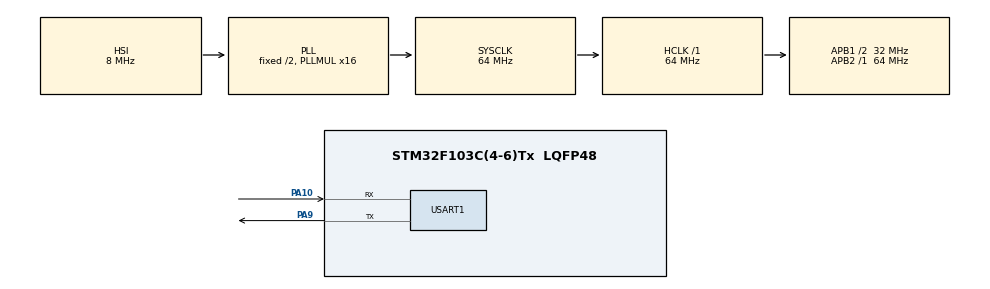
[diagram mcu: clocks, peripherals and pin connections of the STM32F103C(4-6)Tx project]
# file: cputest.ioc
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FREERTOS.Tasks01=defaultTask,0,128,StartDefaultTask,Default,NULL,Dynamic,NULL,NULL;myTask02,-3,128,StartTask02,Default,NULL,Dynamic,NULL,NULL;myTask03,-3,128,StartTask03,Default,NULL,Dynamic,NULL,NULL;monitorTask,-3,128,monitorTaskFun,Default,NULL,Dynamic,NULL,NULL
FREERTOS.configGENERATE_RUN_TIME_STATS=1
FREERTOS.configTOTAL_HEAP_SIZE=5120
FREERTOS.configUSE_STATS_FORMATTING_FUNCTIONS=1
FREERTOS.configUSE_TRACE_FACILITY=1
Mcu.Family=STM32F1
Mcu.Name=STM32F103C(4-6)Tx
Mcu.Package=LQFP48
NVIC.PriorityGroup=NVIC_PRIORITYGROUP_4
NVIC.TIM1_UP_IRQn=true\:15\:0\:false\:false\:true\:false\:false\:true\:true
NVIC.TIM2_IRQn=true\:5\:0\:false\:false\:true\:true\:true\:true\:true
NVIC.TimeBase=TIM1_UP_IRQn
NVIC.TimeBaseIP=TIM1
PA10.Mode=Asynchronous
PA10.Signal=USART1_RX
PA9.Mode=Asynchronous
PA9.Signal=USART1_TX
ProjectManager.HeapSize=0x200
ProjectManager.StackSize=0x400
ProjectManager.TargetToolchain=MDK-ARM V5.32
RCC.AHBFreq_Value=64000000
RCC.APB1CLKDivider=RCC_HCLK_DIV2
RCC.APB1Freq_Value=32000000
RCC.APB1TimFreq_Value=64000000
RCC.APB2Freq_Value=64000000
RCC.APB2TimFreq_Value=64000000
RCC.HCLKFreq_Value=64000000
RCC.PLLMUL=RCC_PLL_MUL16
RCC.SYSCLKFreq_VALUE=64000000
RCC.SYSCLKSource=RCC_SYSCLKSOURCE_PLLCLK
RCC.USBFreq_Value=64000000
TIM2.AutoReloadPreload=TIM_AUTORELOAD_PRELOAD_ENABLE
TIM2.Period=49
TIM2.Prescaler=63
USART1.VirtualMode=VM_ASYNC
VP_FREERTOS_VS_CMSIS_V1.Mode=CMSIS_V1
VP_SYS_VS_ND.Mode=No_Debug
VP_SYS_VS_tim1.Mode=TIM1
VP_TIM2_VS_ClockSourceINT.Mode=Internal
board=custom

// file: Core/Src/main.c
/* USER CODE BEGIN Header */
/**
  ******************************************************************************
  * @file           : main.c
  * @brief          : Main program body
  ******************************************************************************
  * @attention
  *
  * Copyright (c) 2023 STMicroelectronics.
  * All rights reserved.
  *
  * This software is licensed under terms that can be found in the LICENSE file
  * in the root directory of this software component.
  * If no LICENSE file comes with this software, it is provided AS-IS.
  *
  ******************************************************************************
  */
/* USER CODE END Header */
#include "main.h"
#include "cmsis_os.h"
#include "tim.h"
#include "usart.h"
#include "gpio.h"

/* USER CODE BEGIN Includes */
#include <stdio.h>
#include <string.h>
/* USER CODE END Includes */

void SystemClock_Config(void);
void MX_FREERTOS_Init(void);

int main(void)
{

  /* MCU Configuration--------------------------------------------------------*/

  /* Reset of all peripherals, Initializes the Flash interface and the Systick. */
  HAL_Init();

  /* Configure the system clock */
  SystemClock_Config();

  /* Initialize all configured peripherals */
  MX_GPIO_Init();
  MX_USART1_UART_Init();
  MX_TIM2_Init();
	HAL_TIM_Base_Start_IT(&htim2);    // 开启定时器中断

  /* Call init function for freertos objects (in freertos.c) */
  MX_FREERTOS_Init();

  /* Start scheduler */
  osKernelStart();

  /* We should never get here as control is now taken by the scheduler */
  /* Infinite loop */
  while (1)
  {

  }
}

void SystemClock_Config(void)
{
  RCC_OscInitTypeDef RCC_OscInitStruct = {0};
  RCC_ClkInitTypeDef RCC_ClkInitStruct = {0};

  /** Initializes the RCC Oscillators according to the specified parameters
  * in the RCC_OscInitTypeDef structure.
  */
  RCC_OscInitStruct.OscillatorType = RCC_OSCILLATORTYPE_HSI;
  RCC_OscInitStruct.HSIState = RCC_HSI_ON;
  RCC_OscInitStruct.HSICalibrationValue = RCC_HSICALIBRATION_DEFAULT;
  RCC_OscInitStruct.PLL.PLLState = RCC_PLL_ON;
  RCC_OscInitStruct.PLL.PLLSource = RCC_PLLSOURCE_HSI_DIV2;
  RCC_OscInitStruct.PLL.PLLMUL = RCC_PLL_MUL16;
  if (HAL_RCC_OscConfig(&RCC_OscInitStruct) != HAL_OK)
  {
    Error_Handler();
  }

  /** Initializes the CPU, AHB and APB buses clocks
  */
  RCC_ClkInitStruct.ClockType = RCC_CLOCKTYPE_HCLK|RCC_CLOCKTYPE_SYSCLK
                              |RCC_CLOCKTYPE_PCLK1|RCC_CLOCKTYPE_PCLK2;
  RCC_ClkInitStruct.SYSCLKSource = RCC_SYSCLKSOURCE_PLLCLK;
  RCC_ClkInitStruct.AHBCLKDivider = RCC_SYSCLK_DIV1;
  RCC_ClkInitStruct.APB1CLKDivider = RCC_HCLK_DIV2;
  RCC_ClkInitStruct.APB2CLKDivider = RCC_HCLK_DIV1;

  if (HAL_RCC_ClockConfig(&RCC_ClkInitStruct, FLASH_LATENCY_2) != HAL_OK)
  {
    Error_Handler();
  }
}

void HAL_TIM_PeriodElapsedCallback(TIM_HandleTypeDef *htim)
{
  if (htim->Instance == TIM1) {
    HAL_IncTick();
  }
  /* USER CODE BEGIN Callback 1 */
	if (htim->Instance == TIM2) {
    CPU_RunTime++;
  }
  /* USER CODE END Callback 1 */
}

void Error_Handler(void)
{
  __disable_irq();
  while (1)
  {
  }
}

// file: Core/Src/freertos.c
/* USER CODE BEGIN Header */
/**
  ******************************************************************************
  * File Name          : freertos.c
  * Description        : Code for freertos applications
  ******************************************************************************
  * @attention
  *
  * Copyright (c) 2023 STMicroelectronics.
  * All rights reserved.
  *
  * This software is licensed under terms that can be found in the LICENSE file
  * in the root directory of this software component.
  * If no LICENSE file comes with this software, it is provided AS-IS.
  *
  ******************************************************************************
  */
/* USER CODE END Header */

#include "FreeRTOS.h"
#include "task.h"
#include "main.h"
#include "cmsis_os.h"

/* USER CODE BEGIN Includes */
#include <stdio.h>
#include <string.h>
/* USER CODE END Includes */

/* USER CODE BEGIN PTD */
uint32_t CPU_RunTime;
/* USER CODE END PTD */

osThreadId defaultTaskHandle;
osThreadId myTask02Handle;
osThreadId myTask03Handle;
osThreadId monitorTaskHandle;

void StartDefaultTask(void const * argument);
void StartTask02(void const * argument);
void StartTask03(void const * argument);
void monitorTaskFun(void const * argument);

void MX_FREERTOS_Init(void); /* (MISRA C 2004 rule 8.1) */

/* GetIdleTaskMemory prototype (linked to static allocation support) */
void vApplicationGetIdleTaskMemory( StaticTask_t **ppxIdleTaskTCBBuffer, StackType_t **ppxIdleTaskStackBuffer, uint32_t *pulIdleTaskStackSize );

/* Hook prototypes */
void configureTimerForRunTimeStats(void);
unsigned long getRunTimeCounterValue(void);

/* USER CODE BEGIN 1 */
/* Functions needed when configGENERATE_RUN_TIME_STATS is on */
__weak void configureTimerForRunTimeStats(void)
{
	CPU_RunTime = 0ul;
}

__weak unsigned long getRunTimeCounterValue(void)
{
return CPU_RunTime;//g_osRuntimeCounter;
}
/* USER CODE END 1 */

/* USER CODE BEGIN GET_IDLE_TASK_MEMORY */
static StaticTask_t xIdleTaskTCBBuffer;
static StackType_t xIdleStack[configMINIMAL_STACK_SIZE];

void vApplicationGetIdleTaskMemory( StaticTask_t **ppxIdleTaskTCBBuffer, StackType_t **ppxIdleTaskStackBuffer, uint32_t *pulIdleTaskStackSize )
{
  *ppxIdleTaskTCBBuffer = &xIdleTaskTCBBuffer;
  *ppxIdleTaskStackBuffer = &xIdleStack[0];
  *pulIdleTaskStackSize = configMINIMAL_STACK_SIZE;
  /* place for user code */
}
/* USER CODE END GET_IDLE_TASK_MEMORY */

void MX_FREERTOS_Init(void) {

  /* Create the thread(s) */
  /* definition and creation of defaultTask */
  osThreadDef(defaultTask, StartDefaultTask, osPriorityIdle, 0, 128);
  defaultTaskHandle = osThreadCreate(osThread(defaultTask), NULL);

  /* definition and creation of myTask02 */
  osThreadDef(myTask02, StartTask02, osPriorityIdle, 0, 128);
  myTask02Handle = osThreadCreate(osThread(myTask02), NULL);

  /* definition and creation of myTask03 */
  osThreadDef(myTask03, StartTask03, osPriorityIdle, 0, 128);
  myTask03Handle = osThreadCreate(osThread(myTask03), NULL);

  /* definition and creation of monitorTask */
  osThreadDef(monitorTask, monitorTaskFun, osPriorityIdle, 0, 512);
  monitorTaskHandle = osThreadCreate(osThread(monitorTask), NULL);

}

void StartDefaultTask(void const * argument)
{
  /* USER CODE BEGIN StartDefaultTask */
  /* Infinite loop */
	uint8_t i,j;
	uint16_t k=0;
  for(;;)
  {
		for ( i=0; i<255; i++ ) {
			for ( j=0; j<255; j++ ) {
				k += j;osDelay(10);
			}
		}
    osDelay(1);osDelay(100);
  }
  /* USER CODE END StartDefaultTask */
}

void StartTask02(void const * argument)
{
  /* USER CODE BEGIN StartTask02 */
  /* Infinite loop */
	uint8_t i,j;
	uint16_t k=0;
  for(;;)
  {
		for ( i=0; i<255; i++ ) {
			for ( j=0; j<255; j++ ) {
				k += j;osDelay(10);
			}
		}
    osDelay(100);
  }
  /* USER CODE END StartTask02 */
}

void StartTask03(void const * argument)
{
  /* USER CODE BEGIN StartTask03 */
  /* Infinite loop */
  for(;;)
  {
    osDelay(100);
  }
  /* USER CODE END StartTask03 */
}

void monitorTaskFun(void const * argument)
{
  /* USER CODE BEGIN monitorTaskFun */
  /* Infinite loop */

	uint8_t CPU_RunInfo[400];
	//uint8_t *CPU_RunInfo = pvPortMalloc(400);
  for(;;)
  {

		printf("当前剩余内存:%d",xPortGetFreeHeapSize());
		memset(CPU_RunInfo,0,400); //信息缓冲区清零

		vTaskList((char *)&CPU_RunInfo); //获取任务运行时间信息

		printf("---------------------------------------------\r\n");
		printf("任务名  任务状态  优先级  剩余栈  任务序号\r\n");
		printf("%s", CPU_RunInfo);
		printf("---------------------------------------------\r\n");

		memset(CPU_RunInfo,0,400); //信息缓冲区清零

		vTaskGetRunTimeStats((char *)&CPU_RunInfo);

		printf("任务名       运行计数       使用率\r\n");
		printf("%s", CPU_RunInfo);
		printf("---------------------------------------------\r\n\n");
    vTaskDelay(1000);
  }
  /* USER CODE END monitorTaskFun */
}
